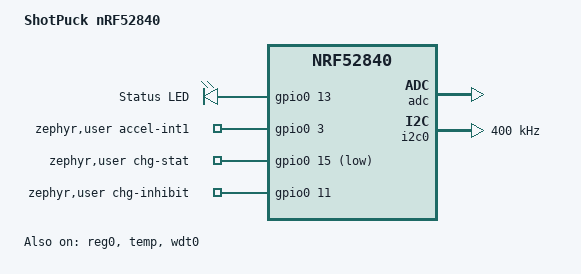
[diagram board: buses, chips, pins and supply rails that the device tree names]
/*
 * ShotPuck - nRF52840 (u-blox BMD-340), VCCH = Li-ion cell.
 *
 * Pin map (BMD-340 pad -> signal):
 *   P0.05 (21) I2C SDA      -> LSM6DSO32 SDA
 *   P0.07 (23) I2C SCL      -> LSM6DSO32 SCL
 *   P0.03 (19) ACCEL_INT1   <- LSM6DSO32 INT1
 *   P0.15 (33) CHG_STAT     <- MCP73831 STAT via BAT54J (low = charging)
 *   P0.11 (27) CHG_INHIBIT  -> Q1B gate (high = charging disabled)
 *   P0.13 (31) LED          -> LED anode via 1k (active high)
 *   VBUS  (66)              <- charger input after reverse-polarity diode, 1k/100n filter
 */
/dts-v1/;
#include <nordic/nrf52840_qiaa.dtsi>
#include "shotpuck_nrf52840-pinctrl.dtsi"

/ {
	model = "ShotPuck nRF52840";
	compatible = "shotpuck,shotpuck-nrf52840";

	chosen {
		zephyr,sram = &sram0;
		zephyr,flash = &flash0;
		zephyr,code-partition = &slot0_partition;
		zephyr,settings-partition = &storage_partition;
	};

	leds {
		compatible = "gpio-leds";
		led0: led_0 {
			gpios = <&gpio0 13 GPIO_ACTIVE_HIGH>;
			label = "Status LED";
		};
	};

	zephyr,user {
		accel-int1-gpios = <&gpio0 3 GPIO_ACTIVE_HIGH>;
		chg-stat-gpios = <&gpio0 15 GPIO_ACTIVE_LOW>;
		chg-inhibit-gpios = <&gpio0 11 GPIO_ACTIVE_HIGH>;
	};

	aliases {
		led0 = &led0;
		watchdog0 = &wdt0;
	};
};

/* No DC/DC inductors assumed: REG0 and REG1 in LDO mode (works on every
 * module variant; see README "decisions" to enable DC/DC). */
&reg0 {
	status = "okay";
};

&reg1 {
	regulator-initial-mode = <NRF5X_REG_MODE_LDO>;
};

&adc {
	status = "okay";
};

&temp {
	status = "okay";
};

&wdt0 {
	status = "okay";
};

&gpiote {
	status = "okay";
};

&gpio0 {
	status = "okay";
};

&gpio1 {
	status = "okay";
};

&i2c0 {
	compatible = "nordic,nrf-twim";
	status = "okay";
	clock-frequency = <I2C_BITRATE_FAST>;
	pinctrl-0 = <&i2c0_default>;
	pinctrl-1 = <&i2c0_sleep>;
	pinctrl-names = "default", "sleep";
};

&flash0 {
	partitions {
		compatible = "fixed-partitions";
		#address-cells = <1>;
		#size-cells = <1>;

		boot_partition: partition@0 {
			label = "mcuboot";
			reg = <0x00000000 0x0000C000>;
		};
		slot0_partition: partition@c000 {
			label = "image-0";
			reg = <0x0000C000 0x00073000>;
		};
		slot1_partition: partition@7f000 {
			label = "image-1";
			reg = <0x0007F000 0x00073000>;
		};
		eventlog_partition: partition@f2000 {
			label = "eventlog";
			reg = <0x000F2000 0x00008000>;
		};
		storage_partition: partition@fa000 {
			label = "storage";
			reg = <0x000FA000 0x00006000>;
		};
	};
};
